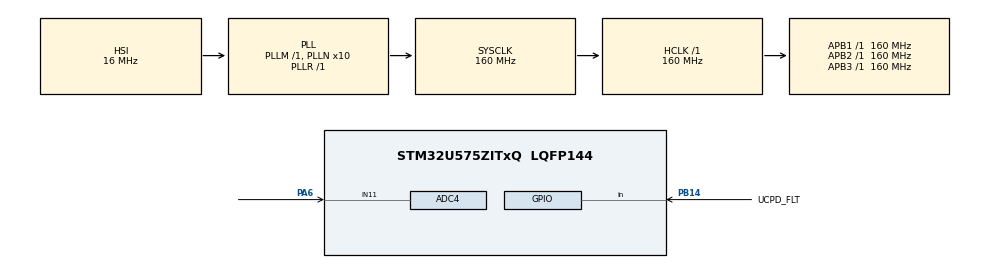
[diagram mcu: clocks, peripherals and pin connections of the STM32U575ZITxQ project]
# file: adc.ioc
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ADC4.ClockPrescaler=ADC_CLOCK_ASYNC_DIV256
ADC4.ContinuousConvMode=ENABLE
ADC4.DMAContinuousRequests=ENABLE
ADC4.NbrOfConversion=1
ADC4.NbrOfConversionFlag=0
ADC4.SelectedChannel=ADC_CHANNEL_11
CORTEX_M33_NS.userName=CORTEX_M33
Mcu.Family=STM32U5
Mcu.Name=STM32U575ZITxQ
Mcu.Package=LQFP144
NVIC.ADC4_IRQn=true\:0\:0\:false\:false\:true\:true\:true\:true
NVIC.PriorityGroup=NVIC_PRIORITYGROUP_3
PA6.Mode=IN11
PA6.Signal=ADC4_IN11
PB14.GPIO_Label=UCPD_FLT
PB14.Signal=GPIO_Input
PB15.GPIO_Label=UCPD1_CC2
PB15.Signal=UCPD1_CC2
PWR.PowerMode=PWR_SMPS_SUPPLY
ProjectManager.HeapSize=0x200
ProjectManager.StackSize=0x400
ProjectManager.TargetToolchain=STM32CubeIDE
RCC.ADCFreq_Value=16000000
RCC.AHBFreq_Value=160000000
RCC.APB1Freq_Value=160000000
RCC.APB1TimFreq_Value=160000000
RCC.APB2Freq_Value=160000000
RCC.APB2TimFreq_Value=160000000
RCC.APB3Freq_Value=160000000
RCC.CortexFreq_Value=160000000
RCC.DACCLockSelectionVirtual=RCC_DAC1CLKSOURCE_LSI
RCC.EPOD_VALUE=16000000
RCC.HCLKFreq_Value=160000000
RCC.HSE_VALUE=16000000
RCC.HSI48_VALUE=48000000
RCC.HSI_VALUE=16000000
RCC.LSIDIV_VALUE=32000
RCC.MSI_VALUE=4000000
RCC.PLL1R=1
RCC.PLLN=10
RCC.PLLSourceVirtual=RCC_PLLSOURCE_HSI
RCC.SYSCLKFreq_VALUE=160000000
RCC.SYSCLKSource=RCC_SYSCLKSOURCE_PLLCLK
RCC.USBFreq_Value=48000000
RCC.VCOOutputFreq_Value=160000000
VP_ICACHE_VS_ENABLE_ICACHE_MEMORY.Mode=Memoryregions
VP_ICACHE_VS_ICACHE.Mode=DirectMappedCache
VP_LPBAMQUEUE_VS_QUEUE.Mode=QUEUEMODE
VP_LPBAM_VS_SIG1.Mode=SmartRun
VP_LPBAM_VS_SIG4.Mode=LPDMA1
VP_MEMORYMAP_VS_MEMORYMAP.Mode=CurAppReg
VP_PWR_VS_DBSignals.Mode=DisableDeadBatterySignals
VP_PWR_VS_LPOM.Mode=PowerOptimisation
VP_PWR_VS_SECSignals.Mode=Security/Privilege
VP_PWR_Vdda.Mode=isolationVdda
board=NUCLEO-U575ZI-Q

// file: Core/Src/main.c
/* USER CODE BEGIN Header */
/**
 ******************************************************************************
 * @file           : main.c
 * @brief          : Main program body
 ******************************************************************************
 * @attention
 *
 * Copyright (c) 2024 STMicroelectronics.
 * All rights reserved.
 *
 * This software is licensed under terms that can be found in the LICENSE file
 * in the root directory of this software component.
 * If no LICENSE file comes with this software, it is provided AS-IS.
 *
 ******************************************************************************
 */
/* USER CODE END Header */
#include "main.h"

ADC_HandleTypeDef hadc4;

/* USER CODE BEGIN PV */
volatile uint32_t value_adc;
/* USER CODE END PV */

void SystemClock_Config(void);
static void SystemPower_Config(void);
static void MX_GPIO_Init(void);
static void MX_ICACHE_Init(void);
static void MX_ADC4_Init(void);

int main(void) {

	/* USER CODE BEGIN 1 */
	int32_t begin = DWT->CYCCNT;
	/* USER CODE END 1 */

	/* MCU Configuration--------------------------------------------------------*/

	/* Reset of all peripherals, Initializes the Flash interface and the Systick. */
	HAL_Init();

	/* Configure the system clock */
	SystemClock_Config();

	/* Configure the System Power */
	SystemPower_Config();

	/* Initialize all configured peripherals */
	MX_GPIO_Init();
	MX_ICACHE_Init();
	MX_ADC4_Init();
	/* USER CODE BEGIN 2 */

	HAL_ADCEx_Calibration_Start(&hadc4, ADC_CALIB_OFFSET, ADC_SINGLE_ENDED);
	HAL_ADC_Start_IT(&hadc4);

	HAL_ADC_PollForConversion(&hadc4, 10000);

	int32_t end = DWT->CYCCNT;
	int32_t diff = end - begin;
	/* USER CODE END 2 */

	/* Infinite loop */
	while (1) {

	}
}

void SystemClock_Config(void) {
	RCC_OscInitTypeDef RCC_OscInitStruct = { 0 };
	RCC_ClkInitTypeDef RCC_ClkInitStruct = { 0 };

	/** Configure the main internal regulator output voltage
	 */
	if (HAL_PWREx_ControlVoltageScaling(PWR_REGULATOR_VOLTAGE_SCALE1)
			!= HAL_OK) {
		Error_Handler();
	}

	/** Initializes the CPU, AHB and APB buses clocks
	 */
	RCC_OscInitStruct.OscillatorType = RCC_OSCILLATORTYPE_HSI;
	RCC_OscInitStruct.HSIState = RCC_HSI_ON;
	RCC_OscInitStruct.HSICalibrationValue = RCC_HSICALIBRATION_DEFAULT;
	RCC_OscInitStruct.PLL.PLLState = RCC_PLL_ON;
	RCC_OscInitStruct.PLL.PLLSource = RCC_PLLSOURCE_HSI;
	RCC_OscInitStruct.PLL.PLLMBOOST = RCC_PLLMBOOST_DIV1;
	RCC_OscInitStruct.PLL.PLLM = 1;
	RCC_OscInitStruct.PLL.PLLN = 10;
	RCC_OscInitStruct.PLL.PLLP = 2;
	RCC_OscInitStruct.PLL.PLLQ = 2;
	RCC_OscInitStruct.PLL.PLLR = 1;
	RCC_OscInitStruct.PLL.PLLRGE = RCC_PLLVCIRANGE_1;
	RCC_OscInitStruct.PLL.PLLFRACN = 0;
	if (HAL_RCC_OscConfig(&RCC_OscInitStruct) != HAL_OK) {
		Error_Handler();
	}

	/** Initializes the CPU, AHB and APB buses clocks
	 */
	RCC_ClkInitStruct.ClockType = RCC_CLOCKTYPE_HCLK | RCC_CLOCKTYPE_SYSCLK
			| RCC_CLOCKTYPE_PCLK1 | RCC_CLOCKTYPE_PCLK2 | RCC_CLOCKTYPE_PCLK3;
	RCC_ClkInitStruct.SYSCLKSource = RCC_SYSCLKSOURCE_PLLCLK;
	RCC_ClkInitStruct.AHBCLKDivider = RCC_SYSCLK_DIV1;
	RCC_ClkInitStruct.APB1CLKDivider = RCC_HCLK_DIV1;
	RCC_ClkInitStruct.APB2CLKDivider = RCC_HCLK_DIV1;
	RCC_ClkInitStruct.APB3CLKDivider = RCC_HCLK_DIV1;

	if (HAL_RCC_ClockConfig(&RCC_ClkInitStruct, FLASH_LATENCY_4) != HAL_OK) {
		Error_Handler();
	}
}

/**
 * @brief Power Configuration
 * @retval None
 */
static void SystemPower_Config(void) {

	/*
	 * Disable the internal Pull-Up in Dead Battery pins of UCPD peripheral
	 */
	HAL_PWREx_DisableUCPDDeadBattery();

	/*
	 * Switch to SMPS regulator instead of LDO
	 */
	if (HAL_PWREx_ConfigSupply(PWR_SMPS_SUPPLY) != HAL_OK) {
		Error_Handler();
	}
}

static void MX_ADC4_Init(void) {

	ADC_ChannelConfTypeDef sConfig = { 0 };

	/** Common config
	 */
	hadc4.Instance = ADC4;
	hadc4.Init.ClockPrescaler = ADC_CLOCK_ASYNC_DIV256;
	hadc4.Init.Resolution = ADC_RESOLUTION_12B;
	hadc4.Init.DataAlign = ADC_DATAALIGN_RIGHT;
	hadc4.Init.ScanConvMode = ADC_SCAN_DIRECTION_FORWARD;
	hadc4.Init.EOCSelection = ADC_EOC_SINGLE_CONV;
	hadc4.Init.LowPowerAutoPowerOff = ADC_LOW_POWER_NONE;
	hadc4.Init.LowPowerAutoWait = DISABLE;
	hadc4.Init.ContinuousConvMode = ENABLE;
	hadc4.Init.NbrOfConversion = 1;
	hadc4.Init.ExternalTrigConv = ADC_SOFTWARE_START;
	hadc4.Init.ExternalTrigConvEdge = ADC_EXTERNALTRIGCONVEDGE_NONE;
	hadc4.Init.DMAContinuousRequests = ENABLE;
	hadc4.Init.TriggerFrequencyMode = ADC_TRIGGER_FREQ_LOW;
	hadc4.Init.Overrun = ADC_OVR_DATA_PRESERVED;
	hadc4.Init.SamplingTimeCommon1 = ADC4_SAMPLETIME_1CYCLE_5;
	hadc4.Init.SamplingTimeCommon2 = ADC4_SAMPLETIME_1CYCLE_5;
	hadc4.Init.OversamplingMode = DISABLE;
	if (HAL_ADC_Init(&hadc4) != HAL_OK) {
		Error_Handler();
	}

	/** Configure Regular Channel
	 */
	sConfig.Channel = ADC_CHANNEL_11;
	sConfig.Rank = ADC4_RANK_CHANNEL_NUMBER;
	sConfig.SamplingTime = ADC4_SAMPLINGTIME_COMMON_1;
	sConfig.OffsetNumber = ADC_OFFSET_NONE;
	sConfig.Offset = 0;
	if (HAL_ADC_ConfigChannel(&hadc4, &sConfig) != HAL_OK) {
		Error_Handler();
	}

}

static void MX_ICACHE_Init(void) {

	/** Enable instruction cache in 1-way (direct mapped cache)
	 */
	if (HAL_ICACHE_ConfigAssociativityMode(ICACHE_1WAY) != HAL_OK) {
		Error_Handler();
	}
	if (HAL_ICACHE_Enable() != HAL_OK) {
		Error_Handler();
	}

}

static void MX_GPIO_Init(void) {
	GPIO_InitTypeDef GPIO_InitStruct = { 0 };

	/* GPIO Ports Clock Enable */
	__HAL_RCC_GPIOA_CLK_ENABLE();
	__HAL_RCC_GPIOB_CLK_ENABLE();

	/*Configure GPIO pin : UCPD_FLT_Pin */
	GPIO_InitStruct.Pin = UCPD_FLT_Pin;
	GPIO_InitStruct.Mode = GPIO_MODE_INPUT;
	GPIO_InitStruct.Pull = GPIO_NOPULL;
	HAL_GPIO_Init(UCPD_FLT_GPIO_Port, &GPIO_InitStruct);

	/*Configure GPIO pin : UCPD1_CC2_Pin */
	GPIO_InitStruct.Pin = UCPD1_CC2_Pin;
	GPIO_InitStruct.Mode = GPIO_MODE_ANALOG;
	GPIO_InitStruct.Pull = GPIO_NOPULL;
	HAL_GPIO_Init(UCPD1_CC2_GPIO_Port, &GPIO_InitStruct);

}

void Error_Handler(void) {
	__disable_irq();
	while (1) {
	}
}
